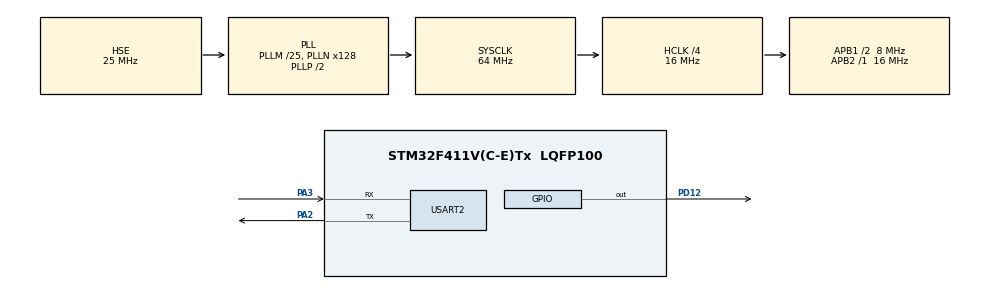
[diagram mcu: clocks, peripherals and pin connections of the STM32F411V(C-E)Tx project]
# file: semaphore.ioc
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FREERTOS.Tasks01=defaultTask,0,128,StartDefaultTask,Default,NULL,Dynamic,NULL,NULL
Mcu.Family=STM32F4
Mcu.Name=STM32F411V(C-E)Tx
Mcu.Package=LQFP100
NVIC.PriorityGroup=NVIC_PRIORITYGROUP_4
PA13.Mode=Serial_Wire
PA13.Signal=SYS_JTMS-SWDIO
PA14.Mode=Serial_Wire
PA14.Signal=SYS_JTCK-SWCLK
PA2.Mode=Asynchronous
PA2.Signal=USART2_TX
PA3.Mode=Asynchronous
PA3.Signal=USART2_RX
PD12.Signal=GPIO_Output
PH0\ -\ OSC_IN.Mode=HSE-External-Oscillator
PH0\ -\ OSC_IN.Signal=RCC_OSC_IN
PH1\ -\ OSC_OUT.Mode=HSE-External-Oscillator
PH1\ -\ OSC_OUT.Signal=RCC_OSC_OUT
ProjectManager.HeapSize=0x200
ProjectManager.StackSize=0x400
ProjectManager.TargetToolchain=STM32CubeIDE
RCC.48MHZClocksFreq_Value=32000000
RCC.AHBCLKDivider=RCC_SYSCLK_DIV4
RCC.AHBFreq_Value=16000000
RCC.APB1CLKDivider=RCC_HCLK_DIV2
RCC.APB1Freq_Value=8000000
RCC.APB1TimFreq_Value=16000000
RCC.APB2Freq_Value=16000000
RCC.APB2TimFreq_Value=16000000
RCC.CortexFreq_Value=16000000
RCC.HCLKFreq_Value=16000000
RCC.HSE_VALUE=25000000
RCC.HSI_VALUE=16000000
RCC.LSE_VALUE=32768
RCC.PLLM=25
RCC.PLLN=128
RCC.PLLSourceVirtual=RCC_PLLSOURCE_HSE
RCC.SYSCLKFreq_VALUE=64000000
RCC.SYSCLKSource=RCC_SYSCLKSOURCE_PLLCLK
RCC.VCOOutputFreq_Value=128000000
USART2.VirtualMode=VM_ASYNC
VP_FREERTOS_VS_CMSIS_V1.Mode=CMSIS_V1
board=custom

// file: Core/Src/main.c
/* USER CODE BEGIN Header */
/**
  ******************************************************************************
  * @file           : main.c
  * @brief          : Main program body
  ******************************************************************************
  * @attention
  *
  * Copyright (c) 2023 STMicroelectronics.
  * All rights reserved.
  *
  * This software is licensed under terms that can be found in the LICENSE file
  * in the root directory of this software component.
  * If no LICENSE file comes with this software, it is provided AS-IS.
  *
  ******************************************************************************
  */
/* USER CODE END Header */
#include "main.h"
#include "cmsis_os.h"

/* USER CODE BEGIN Includes */
#include "stdio.h"
#include "math.h"
#include "string.h"
/* USER CODE END Includes */

UART_HandleTypeDef huart2;

osThreadId defaultTaskHandle;
/* USER CODE BEGIN PV */
TaskHandle_t manager_handle;
TaskHandle_t employee_handle;
SemaphoreHandle_t mySem;
QueueHandle_t myQueue;
char user_msg[100] = {0};
/* USER CODE END PV */

void SystemClock_Config(void);
static void MX_GPIO_Init(void);
static void MX_USART2_UART_Init(void);
//void StartDefaultTask(void const * argument);

/* USER CODE BEGIN PFP */
void task_manager(void);
void task_employee(void);
/* USER CODE END PFP */

int main(void)
{

  /* MCU Configuration--------------------------------------------------------*/

  /* Reset of all peripherals, Initializes the Flash interface and the Systick. */
  HAL_Init();

  /* Configure the system clock */
  SystemClock_Config();

  /* Initialize all configured peripherals */
  MX_GPIO_Init();
  MX_USART2_UART_Init();

  /* USER CODE BEGIN RTOS_SEMAPHORES */
  /* add semaphores, ... */
  vSemaphoreCreateBinary(mySem);
  /* USER CODE END RTOS_SEMAPHORES */

  /* USER CODE BEGIN RTOS_QUEUES */
  /* add queues, ... */
  myQueue = xQueueCreate(10, sizeof(unsigned int));
  /* USER CODE END RTOS_QUEUES */

  /* Create the thread(s) */
  /* definition and creation of defaultTask */
//  osThreadDef(defaultTask, StartDefaultTask, osPriorityNormal, 0, 128);
//  defaultTaskHandle = osThreadCreate(osThread(defaultTask), NULL);

  /* USER CODE BEGIN RTOS_THREADS */
  /* add threads, ... */
  if(mySem != NULL && myQueue != NULL)
  {
	  xTaskCreate(task_manager, "Task manager", 128, NULL, 3, manager_handle);
	  xTaskCreate(task_employee, "Task employee", 128, NULL, 2, employee_handle);

  }
  else
  {
	  sprintf(user_msg, "Queue/ Semaphore are not created!\r\n");
	  HAL_UART_Transmit(&huart2, (uint8_t*)user_msg, strlen(user_msg), 1000);

  }
  /* USER CODE END RTOS_THREADS */

  /* Start scheduler */
  osKernelStart();
  /* We should never get here as control is now taken by the scheduler */
  /* Infinite loop */
  while (1)
  {

  }
}

void SystemClock_Config(void)
{
  RCC_OscInitTypeDef RCC_OscInitStruct = {0};
  RCC_ClkInitTypeDef RCC_ClkInitStruct = {0};

  /** Configure the main internal regulator output voltage
  */
  __HAL_RCC_PWR_CLK_ENABLE();
  __HAL_PWR_VOLTAGESCALING_CONFIG(PWR_REGULATOR_VOLTAGE_SCALE1);

  /** Initializes the RCC Oscillators according to the specified parameters
  * in the RCC_OscInitTypeDef structure.
  */
  RCC_OscInitStruct.OscillatorType = RCC_OSCILLATORTYPE_HSE;
  RCC_OscInitStruct.HSEState = RCC_HSE_ON;
  RCC_OscInitStruct.PLL.PLLState = RCC_PLL_ON;
  RCC_OscInitStruct.PLL.PLLSource = RCC_PLLSOURCE_HSE;
  RCC_OscInitStruct.PLL.PLLM = 25;
  RCC_OscInitStruct.PLL.PLLN = 128;
  RCC_OscInitStruct.PLL.PLLP = RCC_PLLP_DIV2;
  RCC_OscInitStruct.PLL.PLLQ = 4;
  if (HAL_RCC_OscConfig(&RCC_OscInitStruct) != HAL_OK)
  {
    Error_Handler();
  }

  /** Initializes the CPU, AHB and APB buses clocks
  */
  RCC_ClkInitStruct.ClockType = RCC_CLOCKTYPE_HCLK|RCC_CLOCKTYPE_SYSCLK
                              |RCC_CLOCKTYPE_PCLK1|RCC_CLOCKTYPE_PCLK2;
  RCC_ClkInitStruct.SYSCLKSource = RCC_SYSCLKSOURCE_PLLCLK;
  RCC_ClkInitStruct.AHBCLKDivider = RCC_SYSCLK_DIV4;
  RCC_ClkInitStruct.APB1CLKDivider = RCC_HCLK_DIV2;
  RCC_ClkInitStruct.APB2CLKDivider = RCC_HCLK_DIV1;

  if (HAL_RCC_ClockConfig(&RCC_ClkInitStruct, FLASH_LATENCY_0) != HAL_OK)
  {
    Error_Handler();
  }
}

static void MX_USART2_UART_Init(void)
{

  huart2.Instance = USART2;
  huart2.Init.BaudRate = 115200;
  huart2.Init.WordLength = UART_WORDLENGTH_8B;
  huart2.Init.StopBits = UART_STOPBITS_1;
  huart2.Init.Parity = UART_PARITY_NONE;
  huart2.Init.Mode = UART_MODE_TX_RX;
  huart2.Init.HwFlowCtl = UART_HWCONTROL_NONE;
  huart2.Init.OverSampling = UART_OVERSAMPLING_16;
  if (HAL_UART_Init(&huart2) != HAL_OK)
  {
    Error_Handler();
  }

}

static void MX_GPIO_Init(void)
{
  GPIO_InitTypeDef GPIO_InitStruct = {0};

  /* GPIO Ports Clock Enable */
  __HAL_RCC_GPIOH_CLK_ENABLE();
  __HAL_RCC_GPIOA_CLK_ENABLE();
  __HAL_RCC_GPIOD_CLK_ENABLE();

  /*Configure GPIO pin Output Level */
  HAL_GPIO_WritePin(GPIOD, GPIO_PIN_12, GPIO_PIN_RESET);

  /*Configure GPIO pin : PD12 */
  GPIO_InitStruct.Pin = GPIO_PIN_12;
  GPIO_InitStruct.Mode = GPIO_MODE_OUTPUT_PP;
  GPIO_InitStruct.Pull = GPIO_NOPULL;
  GPIO_InitStruct.Speed = GPIO_SPEED_FREQ_LOW;
  HAL_GPIO_Init(GPIOD, &GPIO_InitStruct);

}

/* USER CODE BEGIN 4 */
void task_manager(void)
{
	unsigned int time;
	BaseType_t status;
	xSemaphoreGive(mySem);
	while(1)
	{
		time = (rand() & 0xff);
		status = xQueueSend(myQueue, &time, portMAX_DELAY);
		if(status == pdTRUE)
		{
			xSemaphoreGive(mySem);
			taskYIELD();
		}
	}
}

void task_employee(void)
{
	unsigned int time;
	BaseType_t status;
	while(1)
	{
		xSemaphoreTake(mySem, 0);
		status = xQueueReceive(myQueue, &time, portMAX_DELAY);
		if(status == pdTRUE)
		{
			HAL_GPIO_TogglePin(GPIOD, GPIO_PIN_12);
			sprintf(user_msg, "Time to delay: %d\r\n", time);
			HAL_UART_Transmit(&huart2, (uint8_t *)user_msg, strlen(user_msg), 1000);
			memset(user_msg, 0, 100);
			vTaskDelay(pdMS_TO_TICKS(time));
		}
	}
}
/* USER CODE END 4 */

//void StartDefaultTask(void const * argument)
//{
//  /* USER CODE BEGIN 5 */
////  /* Infinite loop */
////  for(;;)
////  {
////    osDelay(1);
////  }
//  /* USER CODE END 5 */
//}

void Error_Handler(void)
{
  __disable_irq();
  while (1)
  {
  }
}
